# PY32F040xx register map
Vendor: Puya; Series: PY32F0; File version: 1.0.0
CPU: CM0+ r0p1, little endian, no MPU, no FPU, 4 interrupt priority bits
Registers are 32-bit, read-write, reset 0x0 unless marked. A register's access mark holds for its fields unless they carry their own. Offsets are from the block's base; [hi:lo] are bit positions; {n}, {i} and the like mark numbered series.

## FLASH
Base 0x40022000
0x00 ACR reset 0x500
  [1:0] LATENCY
    0=WS0 (0 wait states); 1=WS1 (1 wait state)
0x08 KEYR wo
  [31:0] KEY
0x0C OPTKEYR wo
  [31:0] OPTKEY
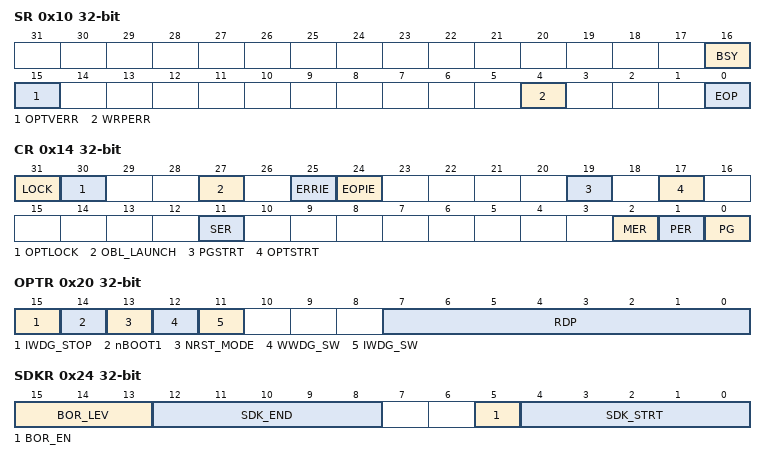
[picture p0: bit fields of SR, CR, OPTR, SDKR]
0x10 SR
  [16] BSY ro
    0=Inactive (No write/erase operation is in progress); 1=Active (A write/erase operation is in progress)
  [15] OPTVERR
    0=NoError (No option and Engineering bits loading validity error occurred); 1=Error (An option and Engineering bits loading validity error occurred)
  [4] WRPERR
    0=NoError (No write protection error occurred); 1=Error (A write protection error occurred)
  [0] EOP
    0=NoEvent (No EOP operation occurred); 1=Event (An EOP event occurred)
0x14 CR
  [31] LOCK
    0=Unlocked (FLASH_CR register is unlocked); 1=Locked (FLASH_CR register is locked)
  [30] OPTLOCK
    0=Unlocked (Options is unlocked); 1=Locked (Options is locked)
  [27] OBL_LAUNCH
    0=Inactive (Force option byte loading inactive); 1=Active (Force option byte loading active)
  [25] ERRIE
    0=Disabled (Error interrupt generation disabled); 1=Enabled (Error interrupt generation enabled)
  [24] EOPIE
    0=Disabled (End of operation interrupt disabled); 1=Enabled (End of operation interrupt enabled)
  [19] PGSTRT
  [17] OPTSTRT
    1=Option byte program start
  [11] SER
    1=SectorErase (Erase activated for user sectors)
  [2] MER
    1=MassErase (Erase activated for all user sectors)
  [1] PER
    1=PageErase (Erase activated for selected page)
  [0] PG
    1=Program (Flash programming activated)
0x20 OPTR ro
  [15] IWDG_STOP
  [14] nBOOT1
    0=Clear (Select boot mode together with BOOT Pin); 1=Set (Select boot mode together with BOOT Pin)
  [13] NRST_MODE
    0=NRST (Configure as NRST pin); 1=GPIO (Configure as GPIO pin)
  [12] WWDG_SW
    0=Hardware window watchdog; 1=Software window watchdog
  [11] IWDG_SW
  [7:0] RDP
    136=Level 1, memories readout protection active (writes 0x88); 170=Level 0, readout protection not active; 204=Level 2, chip readout protection active
0x24 SDKR ro
  [15:13] BOR_LEV, [12:8] SDK_END, [5] BOR_EN, [4:0] SDK_STRT
0x2C WRPR
  [15:0] WRP
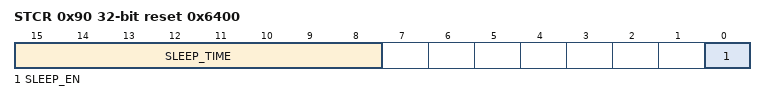
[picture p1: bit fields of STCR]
0x90 STCR reset 0x6400
  [15:8] SLEEP_TIME, [0] SLEEP_EN
0x100 TS0 reset 0xB4
  [7:0] TS0
0x104 TS1 reset 0x1B0
  [8:0] TS1
0x108 TS2P reset 0xB4
  [7:0] TS2P
0x10C TPS3 reset 0x6C0
  [10:0] TPS3
0x110 TS3 reset 0xB4
  [7:0] TS3
0x114 PERTPE reset 0xEA60
  [16:0] PERTPE
0x118 SMERTPE reset 0xFD20
  [16:0] SMERTPE
0x11C PRGTPE reset 0x8CA0
  [15:0] PRGTPE
0x120 PRETPE reset 0x12C0
  [13:0] PRETPE

## GPIOA — General-purpose I/Os
Base 0x50000000
Same registers: GPIOB 0x50000400, GPIOC 0x50000800, GPIOF 0x50001400
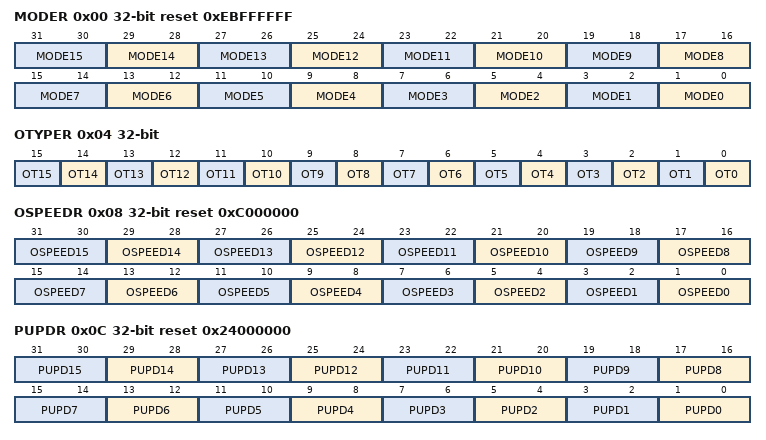
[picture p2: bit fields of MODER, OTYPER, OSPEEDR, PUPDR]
0x00 MODER reset 0xEBFFFFFF — GPIO port mode register
  [all] fields
    0=Input mode; 1=Output (General purpose output mode); 2=Alternate function mode; 3=Analog mode
  [2n+1:2n] MODE{n} (n=0..15) — Port x configuration bits (y=0-15)
0x04 OTYPER — GPIO port output type register
  [all] fields
    0=PushPull (Output push-pull (reset state)); 1=OpenDrain (Output open-drain)
  [n] OT{n} (n=0..15) — Port x configuration bits (y=0-15)
0x08 OSPEEDR reset 0xC000000 — GPIO port output speed register
  [all] fields
    0=LowSpeed; 1=MediumSpeed; 2=HighSpeed; 3=VeryHighSpeed
  [2n+1:2n] OSPEED{n} (n=0..15) — Port x configuration bits (y=0-15)
0x0C PUPDR reset 0x24000000 — GPIO port pull-up/pull-down register
  [all] fields
    0=Floating (No pull-up, pull-down); 1=PullUp; 2=PullDown
  [2n+1:2n] PUPD{n} (n=0..15) — Port x configuration bits (y=0-15)
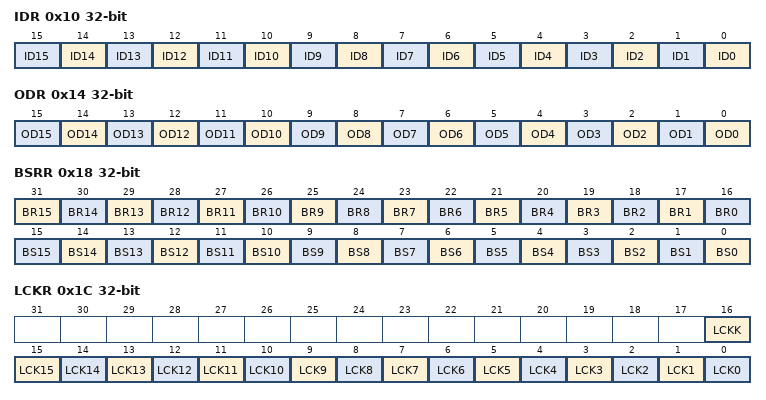
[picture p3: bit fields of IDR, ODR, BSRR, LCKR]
0x10 IDR ro — GPIO port input data register
  [all] fields
    0=Low (Input is logic low); 1=High (Input is logic high)
  [n] ID{n} (n=0..15) — Port input data (y=0-15)
0x14 ODR — GPIO port output data register
  [all] fields
    0=Low (Set output to logic low); 1=High (Set output to logic high)
  [n] OD{n} (n=0..15) — Port output data (y=0-15)
0x18 BSRR wo — GPIO port bit set/reset register
  [n+16] BR{n} (n=1..15) — Port x reset bit y (y=0-15)
    1=Resets the corresponding ODx bit
  [16] BR0 — Port x set bit y (y=0-15)
    1=Resets the corresponding ODx bit
  [n] BS{n} (n=0..15) — Port x set bit y (y=0-15)
    1=Set (Sets the corresponding ODx bit)
0x1C LCKR — GPIO port configuration lock register
  [16] LCKK — Port x lock (LCKK)
    0=NotActive (Port configuration lock key not active); 1=Active (Port configuration lock key active)
  [n] LCK{n} (n=0..15) — Port x lock bit y (y=0-15)
    0=Unlocked (Port configuration not locked); 1=Locked (Port configuration locked)
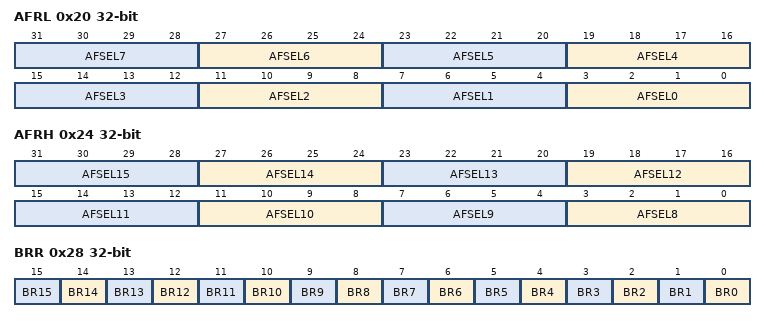
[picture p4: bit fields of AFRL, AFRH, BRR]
0x20 AFRL — GPIO alternate function low register
  [all] fields
    {v}=AF{v} (v=0..15)
  [4n+3:4n] AFSEL{n} (n=0..7) — Alternate function selection for port x bit y (y=0-7)
0x24 AFRH — GPIO alternate function high register
  [all] fields
    {v}=AF{v} (v=0..15)
  [4n-29:4n-32] AFSEL{n} (n=8..15) — Alternate function selection for port x bit y (y=8-15)
0x28 BRR wo — port bit reset register
  [all] fields
    0=No action on the corresponding ODx bit; 1=Reset the ODx bit
  [n] BR{n} (n=0..15) — Port Reset bit
